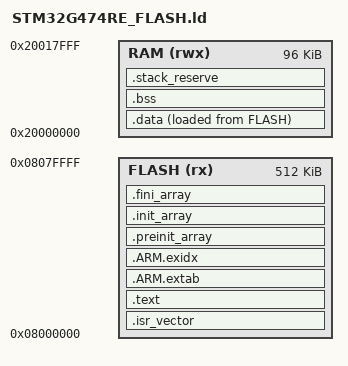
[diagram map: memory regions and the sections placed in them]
/* Project-authored map: 512KiB flash; 96KiB contiguous SRAM1+SRAM2.
 * Separate 32KiB CCM is intentionally unused; DMA cannot use CCM. */
ENTRY(Reset_Handler)
PHDRS { flash PT_LOAD FLAGS(5); ram PT_LOAD FLAGS(6); }
MEMORY { FLASH (rx) : ORIGIN = 0x08000000, LENGTH = 512K
         RAM (rwx) : ORIGIN = 0x20000000, LENGTH = 96K }
_estack = ORIGIN(RAM)+LENGTH(RAM);
SECTIONS {
 .isr_vector : { KEEP(*(.isr_vector)) } > FLASH :flash
 .text : { *(.text*) *(.rodata*) KEEP(*(.init)) KEEP(*(.fini)) . = ALIGN(4); _etext = .; } > FLASH
 .ARM.extab : { *(.ARM.extab*) } > FLASH
 .ARM.exidx : { __exidx_start = .; *(.ARM.exidx*) __exidx_end = .; } > FLASH
 .preinit_array : { PROVIDE_HIDDEN(__preinit_array_start = .); KEEP(*(.preinit_array*)) PROVIDE_HIDDEN(__preinit_array_end = .); } > FLASH
 .init_array : { PROVIDE_HIDDEN(__init_array_start = .); KEEP(*(SORT(.init_array.*))) KEEP(*(.init_array*)) PROVIDE_HIDDEN(__init_array_end = .); } > FLASH
 .fini_array : { PROVIDE_HIDDEN(__fini_array_start = .); KEEP(*(SORT(.fini_array.*))) KEEP(*(.fini_array*)) PROVIDE_HIDDEN(__fini_array_end = .); } > FLASH
 _sidata = LOADADDR(.data);
 .data : { . = ALIGN(4); _sdata = .; *(.data*) . = ALIGN(4); _edata = .; } > RAM AT> FLASH :ram
 .bss (NOLOAD) : { . = ALIGN(8); _sbss = .; *(.bss*) *(COMMON) . = ALIGN(8); _ebss = .; } > RAM
 .stack_reserve (NOLOAD) : { . = ALIGN(8); . += 4096; } > RAM
 ASSERT(_ebss+4096<=_estack,"SRAM overflow including 4KiB stack reserve")
 /DISCARD/ : { *(.note.GNU-stack) }
}
